# cyw20829 register map
Vendor: Infineon Technologies; Series: CYW20829; File version: 1.0
CPU: CM33 r0p1, little endian, MPU, no FPU, VTOR, 3 interrupt priority bits
Registers are 32-bit, read-write, reset 0x0 unless marked. A register's access mark holds for its fields unless they carry their own. Offsets are from the block's base; [hi:lo] are bit positions; lines under a group give offsets from that group; {n}, {i} and the like mark numbered series.

## BTSS — MXS40BLE52SS IP
Base 0x42000000
0x600000 DATA_RAM_IPC group
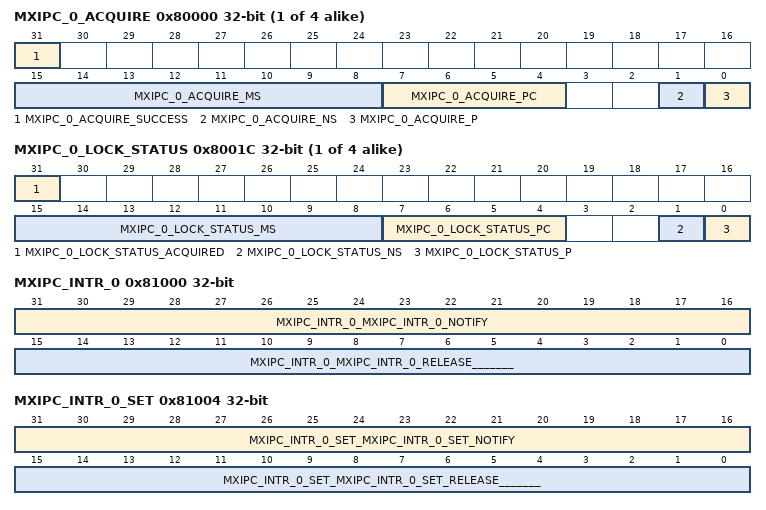
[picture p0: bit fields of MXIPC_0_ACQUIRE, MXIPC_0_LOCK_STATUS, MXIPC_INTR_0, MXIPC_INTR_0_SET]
  {0x80000+0x20*j} MXIPC_{j}_ACQUIRE (reset mask 0x80000000) (j=0..3)
    [31] MXIPC_{j}_ACQUIRE_SUCCESS — Specifies if the lock is successfully acquired or not (reading the ACQUIRE register can have affect on SUCCESS and LOCK_STATUS.ACQUIRED): '0': Not successfully acquired; i.e. the lock was already acquired by another read transaction and not released. The P, NS, PC and MS fields reflect the access attributes of the transaction that previously successfully acuired the lock; the fields are NOT affected by the current access. '1': Successfully acquired. The P, NS, PC and MS fields reflect the access attributes of the current access. Note that this field is NOT SW writable. A lock is released by writing to the associated RELEASE register (irrespective of the write value).
    [15:8] MXIPC_{j}_ACQUIRE_MS ro — This field specifies the bus master identifier ({HMASTER[MASTER_WIDTH-2:0], HMASTER[MASTER_WIDTH}) that successfully acquired the lock. (MASTER_WIDTH = 4)
    [7:4] MXIPC_{j}_ACQUIRE_PC ro — This field specifies the protection context that successfully acquired the lock.
    [1] MXIPC_{j}_ACQUIRE_NS ro — Secure/non-secure access control: '0': secure. '1': non-secure. This field is set with the secure/non-secure access control of the access that successfully acquired the lock.
    [0] MXIPC_{j}_ACQUIRE_P ro — User/privileged access control: '0': user mode. '1': privileged mode. This field is set with the user/privileged access control of the access that successfully acquired the lock.
  {0x80004+0x20*j} MXIPC_{j}_RELEASE (j=0..3)
    [31:0] MXIPC_{j}_RELEASE — Writing this field releases a lock and allows for the generation of release events to the IPC interrupt structures, but only when the lock is acquired (LOCK_STATUS.ACQUIRED is '1'). The IPC release cause fields associated with this IPC structure are set to '1', but only for those IPC interrupt structures for which the corresponding bit field in INTR_RELEASE[] is set to '1'. SW writes a '1' to the bit fields to generate a release event. Due to the transient nature of this event, SW always reads a '0' from this field.
  {0x80008+0x20*j} MXIPC_{j}_NOTIFY (j=0..3)
    [31:0] MXIPC_{j}_NOTIFY — This field allows for the generation of notification events to the IPC interrupt structures. The IPC notification cause fields associated with this IPC structure are set to '1', but only for those IPC interrupt structures for which the corresponding bit field in INTR_NOTIFY[] is set to '1'. SW writes a '1' to the bit fields to generate a notify event. Due to the transient nature of this event, SW always reads a '0' from this field.
  {0x8000C+0x20*j} MXIPC_{j}_DATA0 (j=0..3)
    [31:0] MXIPC_{j}_DATA0 — This field holds a 32-bit data element that is associated with the IPC structure.
  {0x80010+0x20*j} MXIPC_{j}_DATA1 (j=0..3)
    [31:0] MXIPC_{j}_DATA1 — This field holds a 32-bit data element that is associated with the IPC structure.
  {0x8001C+0x20*j} MXIPC_{j}_LOCK_STATUS ro (reset mask 0x80000000) (j=0..3)
    [31] MXIPC_{j}_LOCK_STATUS_ACQUIRED — Specifies if the lock is acquired. This field is set to '1', if a ACQUIRE read transfer successfully acquires the lock (the ACQUIRE read transfer returns ACQUIRE.SUCCESS as '1'). If zero, P, NS, PC, and MS are not valid.
    [15:8] MXIPC_{j}_LOCK_STATUS_MS — This field specifies the bus master identifier ({HMASTER[MASTER_WIDTH-2:0], HMASTER[MASTER_WIDTH}) that successfully acquired the lock. (MASTER_WIDTH = 4)
    [7:4] MXIPC_{j}_LOCK_STATUS_PC — This field specifies the protection context that successfully acquired the lock.
    [1] MXIPC_{j}_LOCK_STATUS_NS — This field specifies the secure/non-secure access control: '0': secure. '1': non-secure.
    [0] MXIPC_{j}_LOCK_STATUS_P — This field specifies the user/privileged access control: '0': user mode. '1': privileged mode.
  0x81000 MXIPC_INTR_0
    [31:16] MXIPC_INTR_0_MXIPC_INTR_0_NOTIFY — These interrupt cause fields are activated (HW sets the field to '1') when a IPC notification event is detected. One bit field for each master. SW writes a '1' to these field to clear the interrupt cause.
    [15:0] MXIPC_INTR_0_MXIPC_INTR_0_RELEASE_______ — These interrupt cause fields are activated (HW sets the field to '1') when a IPC release event is detected. One bit field for each master. SW writes a '1' to these field to clear the interrupt cause.
  0x81004 MXIPC_INTR_0_SET
    [31:16] MXIPC_INTR_0_SET_MXIPC_INTR_0_SET_NOTIFY — SW writes a '1' to this field to set the corresponding field in the INTR register.
    [15:0] MXIPC_INTR_0_SET_MXIPC_INTR_0_SET_RELEASE_______ — SW writes a '1' to this field to set the corresponding field in the INTR register.
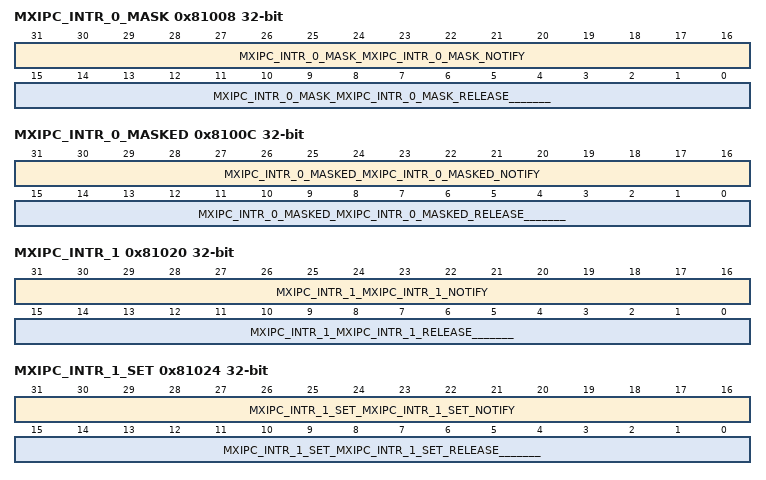
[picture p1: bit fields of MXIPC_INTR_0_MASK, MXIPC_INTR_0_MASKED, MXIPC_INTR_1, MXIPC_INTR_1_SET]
  0x81008 MXIPC_INTR_0_MASK
    [31:16] MXIPC_INTR_0_MASK_MXIPC_INTR_0_MASK_NOTIFY — Mask bit for corresponding field in the INTR register.
    [15:0] MXIPC_INTR_0_MASK_MXIPC_INTR_0_MASK_RELEASE_______ — Mask bit for corresponding field in the INTR register.
  0x8100C MXIPC_INTR_0_MASKED ro
    [31:16] MXIPC_INTR_0_MASKED_MXIPC_INTR_0_MASKED_NOTIFY — Logical and of corresponding INTR and INTR_MASK fields.
    [15:0] MXIPC_INTR_0_MASKED_MXIPC_INTR_0_MASKED_RELEASE_______ — Logical and of corresponding request and mask bits.
  0x81020 MXIPC_INTR_1
    [31:16] MXIPC_INTR_1_MXIPC_INTR_1_NOTIFY — These interrupt cause fields are activated (HW sets the field to '1') when a IPC notification event is detected. One bit field for each master. SW writes a '1' to these field to clear the interrupt cause.
    [15:0] MXIPC_INTR_1_MXIPC_INTR_1_RELEASE_______ — These interrupt cause fields are activated (HW sets the field to '1') when a IPC release event is detected. One bit field for each master. SW writes a '1' to these field to clear the interrupt cause.
  0x81024 MXIPC_INTR_1_SET
    [31:16] MXIPC_INTR_1_SET_MXIPC_INTR_1_SET_NOTIFY — SW writes a '1' to this field to set the corresponding field in the INTR register.
    [15:0] MXIPC_INTR_1_SET_MXIPC_INTR_1_SET_RELEASE_______ — SW writes a '1' to this field to set the corresponding field in the INTR register.
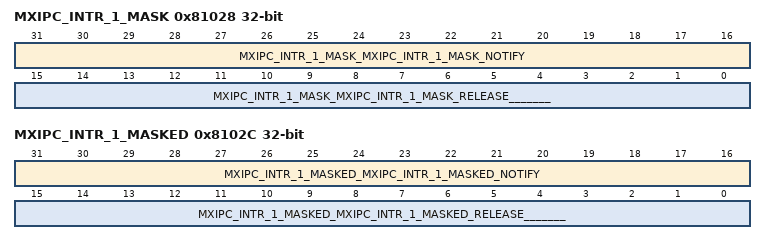
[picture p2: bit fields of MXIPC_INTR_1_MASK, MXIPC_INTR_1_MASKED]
  0x81028 MXIPC_INTR_1_MASK
    [31:16] MXIPC_INTR_1_MASK_MXIPC_INTR_1_MASK_NOTIFY — Mask bit for corresponding field in the INTR register.
    [15:0] MXIPC_INTR_1_MASK_MXIPC_INTR_1_MASK_RELEASE_______ — Mask bit for corresponding field in the INTR register.
  0x8102C MXIPC_INTR_1_MASKED ro
    [31:16] MXIPC_INTR_1_MASKED_MXIPC_INTR_1_MASKED_NOTIFY — Logical and of corresponding INTR and INTR_MASK fields.
    [15:0] MXIPC_INTR_1_MASKED_MXIPC_INTR_1_MASKED_RELEASE_______ — Logical and of corresponding request and mask bits.
